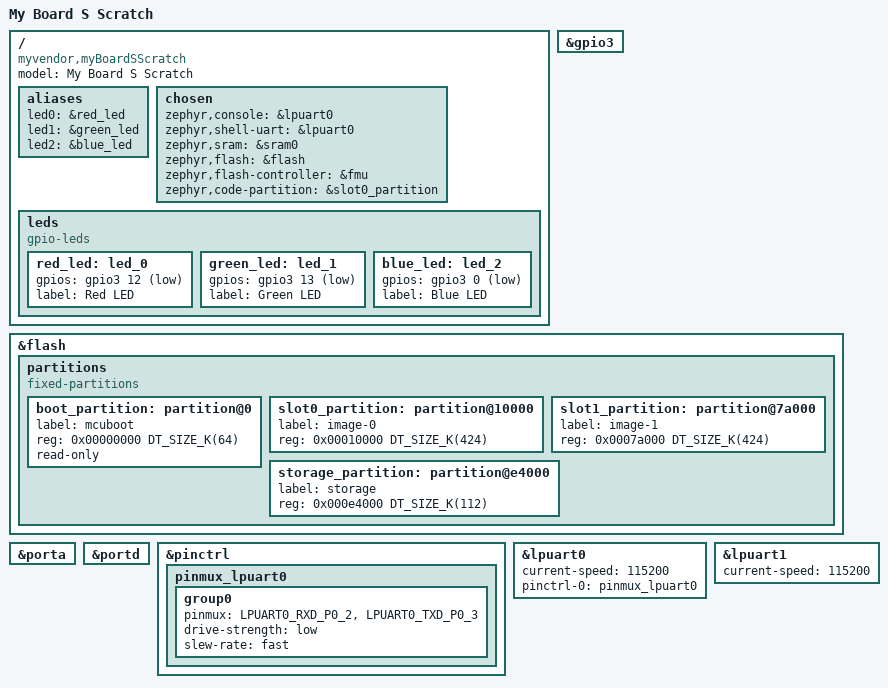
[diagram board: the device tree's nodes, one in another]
/dts-v1/;
#include <nxp/nxp_mcxa156.dtsi>
#include <zephyr/dt-bindings/gpio/gpio.h>
#include <nxp/mcx/MCXA156VLL-pinctrl.h>


/{
	model = "My Board S Scratch";
	compatible = "myvendor,myBoardSScratch";

	aliases {
		led0 = &red_led;
		led1 = &green_led;
		led2 = &blue_led;
	};

	chosen {
		zephyr,console = &lpuart0;
		zephyr,shell-uart = &lpuart0;
		zephyr,sram = &sram0;
		zephyr,flash = &flash;
		zephyr,flash-controller = &fmu;
		zephyr,code-partition = &slot0_partition;
	};

	leds {
		compatible = "gpio-leds";
		red_led: led_0 {
			gpios = <&gpio3 12 GPIO_ACTIVE_LOW>;
			label = "Red LED";
		};
		green_led: led_1 {
			gpios = <&gpio3 13 GPIO_ACTIVE_LOW>;
			label = "Green LED";
		};
		blue_led: led_2 {
			gpios = <&gpio3 0 GPIO_ACTIVE_LOW>;
			label = "Blue LED";
		};
	};
};

&gpio3 {
	status = "okay";
};

&flash {
	partitions {
		compatible = "fixed-partitions";
		#address-cells = <1>;
		#size-cells = <1>;

		boot_partition: partition@0 {
			label = "mcuboot";
			reg = <0x00000000 DT_SIZE_K(64)>;
			read-only;
		};
		slot0_partition: partition@10000 {
			label = "image-0";
			reg = <0x00010000 DT_SIZE_K(424)>;
		};
		slot1_partition: partition@7a000 {
			label = "image-1";
			reg = <0x0007a000 DT_SIZE_K(424)>;
		};
		storage_partition: partition@e4000 {
			label = "storage";
			reg = <0x000e4000 DT_SIZE_K(112)>;
		};
	};
};

&porta {
	status = "okay";
};

&portd {
	status = "okay";
};

&gpio3 {
	status = "okay";
};

&pinctrl {
	pinmux_lpuart0: pinmux_lpuart0 {
		group0 {
			pinmux = <LPUART0_RXD_P0_2>,
				 <LPUART0_TXD_P0_3>;
			drive-strength = "low";
			slew-rate = "fast";
		};
	};
};

&lpuart0 {
	status = "okay";
	current-speed = <115200>;
	pinctrl-0 = <&pinmux_lpuart0>;
	pinctrl-names = "default";
};

&lpuart1 {
	status = "okay";
	current-speed = <115200>;
};
